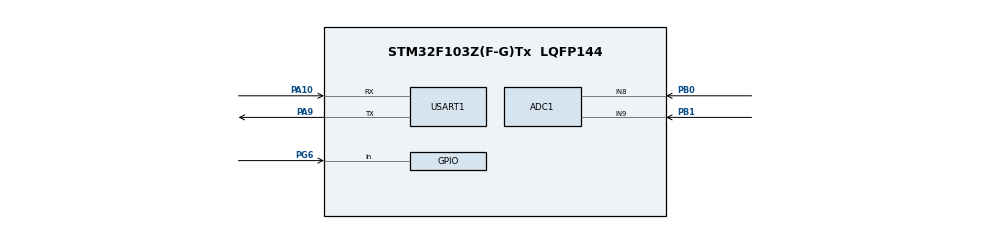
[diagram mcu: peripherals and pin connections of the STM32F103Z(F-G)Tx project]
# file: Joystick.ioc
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ADC1.Channel-2\#ChannelRegularConversion=ADC_CHANNEL_8
ADC1.Channel-3\#ChannelRegularConversion=ADC_CHANNEL_9
ADC1.DiscontinuousConvMode=ENABLE
ADC1.EnableRegularConversion=ENABLE
ADC1.NbrOfConversion=2
ADC1.NbrOfConversionFlag=1
ADC1.NbrOfDiscConversion=1
ADC1.Rank-2\#ChannelRegularConversion=1
ADC1.Rank-3\#ChannelRegularConversion=2
ADC1.SamplingTime-2\#ChannelRegularConversion=ADC_SAMPLETIME_1CYCLE_5
ADC1.SamplingTime-3\#ChannelRegularConversion=ADC_SAMPLETIME_1CYCLE_5
ADC1.master=1
Mcu.Family=STM32F1
Mcu.Name=STM32F103Z(F-G)Tx
Mcu.Package=LQFP144
NVIC.PriorityGroup=NVIC_PRIORITYGROUP_4
PA10.Mode=Asynchronous
PA10.Signal=USART1_RX
PA13.Mode=Serial_Wire
PA13.Signal=SYS_JTMS-SWDIO
PA14.Mode=Serial_Wire
PA14.Signal=SYS_JTCK-SWCLK
PA9.Mode=Asynchronous
PA9.Signal=USART1_TX
PB0.Signal=ADCx_IN8
PB1.Signal=ADCx_IN9
PG6.Signal=GPIO_Input
ProjectManager.HeapSize=0x200
ProjectManager.StackSize=0x400
ProjectManager.TargetToolchain=MDK-ARM V5.27
RCC.APB1Freq_Value=8000000
RCC.APB2Freq_Value=8000000
SH.ADCx_IN8.0=ADC1_IN8,IN8
SH.ADCx_IN9.0=ADC1_IN9,IN9
USART1.VirtualMode=VM_ASYNC
board=custom

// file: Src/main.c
/* USER CODE BEGIN Header */
/**
  ******************************************************************************
  * @file           : main.c
  * @brief          : Main program body
  ******************************************************************************
  * @attention
  *
  * <h2><center>&copy; Copyright (c) 2019 STMicroelectronics.
  * All rights reserved.</center></h2>
  *
  * This software component is licensed by ST under BSD 3-Clause license,
  * the "License"; You may not use this file except in compliance with the
  * License. You may obtain a copy of the License at:
  *                        opensource.org/licenses/BSD-3-Clause
  *
  ******************************************************************************
  */
/* USER CODE END Header */

#include "main.h"

ADC_HandleTypeDef hadc1;

UART_HandleTypeDef huart1;

void SystemClock_Config(void);
static void MX_GPIO_Init(void);
static void MX_ADC1_Init(void);
static void MX_USART1_UART_Init(void);

int main(void)
{

  /* MCU Configuration--------------------------------------------------------*/

  /* Reset of all peripherals, Initializes the Flash interface and the Systick. */
  HAL_Init();

  /* Configure the system clock */
  SystemClock_Config();

  /* Initialize all configured peripherals */
  MX_GPIO_Init();
  MX_ADC1_Init();
  MX_USART1_UART_Init();
  /* USER CODE BEGIN 2 */
  uint32_t x, y;
  /* USER CODE END 2 */

  /* Infinite loop */
  /* USER CODE BEGIN WHILE */
  while (1)
  {
    // Get x position from joystick
  	HAL_ADC_Start(&hadc1);
  	HAL_ADC_PollForConversion(&hadc1, 10);
  	x = HAL_ADC_GetValue(&hadc1);

    // Get y position from joystick
  	HAL_ADC_Start(&hadc1);
  	HAL_ADC_PollForConversion(&hadc1, 10);
  	y = HAL_ADC_GetValue(&hadc1);

    // Print x, y position
  	printf("%d,%d\r\n", x, y);

  	HAL_Delay(10);

    /* USER CODE END WHILE */

  }
}

void SystemClock_Config(void)
{
  RCC_OscInitTypeDef RCC_OscInitStruct = {0};
  RCC_ClkInitTypeDef RCC_ClkInitStruct = {0};
  RCC_PeriphCLKInitTypeDef PeriphClkInit = {0};

  /** Initializes the CPU, AHB and APB busses clocks
  */
  RCC_OscInitStruct.OscillatorType = RCC_OSCILLATORTYPE_HSI;
  RCC_OscInitStruct.HSIState = RCC_HSI_ON;
  RCC_OscInitStruct.HSICalibrationValue = RCC_HSICALIBRATION_DEFAULT;
  RCC_OscInitStruct.PLL.PLLState = RCC_PLL_NONE;
  if (HAL_RCC_OscConfig(&RCC_OscInitStruct) != HAL_OK)
  {
    Error_Handler();
  }
  /** Initializes the CPU, AHB and APB busses clocks
  */
  RCC_ClkInitStruct.ClockType = RCC_CLOCKTYPE_HCLK|RCC_CLOCKTYPE_SYSCLK
                              |RCC_CLOCKTYPE_PCLK1|RCC_CLOCKTYPE_PCLK2;
  RCC_ClkInitStruct.SYSCLKSource = RCC_SYSCLKSOURCE_HSI;
  RCC_ClkInitStruct.AHBCLKDivider = RCC_SYSCLK_DIV1;
  RCC_ClkInitStruct.APB1CLKDivider = RCC_HCLK_DIV1;
  RCC_ClkInitStruct.APB2CLKDivider = RCC_HCLK_DIV1;

  if (HAL_RCC_ClockConfig(&RCC_ClkInitStruct, FLASH_LATENCY_0) != HAL_OK)
  {
    Error_Handler();
  }
  PeriphClkInit.PeriphClockSelection = RCC_PERIPHCLK_ADC;
  PeriphClkInit.AdcClockSelection = RCC_ADCPCLK2_DIV2;
  if (HAL_RCCEx_PeriphCLKConfig(&PeriphClkInit) != HAL_OK)
  {
    Error_Handler();
  }
}

static void MX_ADC1_Init(void)
{

  ADC_ChannelConfTypeDef sConfig = {0};

  /** Common config
  */
  hadc1.Instance = ADC1;
  hadc1.Init.ScanConvMode = ADC_SCAN_ENABLE;
  hadc1.Init.ContinuousConvMode = DISABLE;
  hadc1.Init.DiscontinuousConvMode = ENABLE;
  hadc1.Init.NbrOfDiscConversion = 1;
  hadc1.Init.ExternalTrigConv = ADC_SOFTWARE_START;
  hadc1.Init.DataAlign = ADC_DATAALIGN_RIGHT;
  hadc1.Init.NbrOfConversion = 2;
  if (HAL_ADC_Init(&hadc1) != HAL_OK)
  {
    Error_Handler();
  }
  /** Configure Regular Channel
  */
  sConfig.Channel = ADC_CHANNEL_8;
  sConfig.Rank = ADC_REGULAR_RANK_1;
  sConfig.SamplingTime = ADC_SAMPLETIME_1CYCLE_5;
  if (HAL_ADC_ConfigChannel(&hadc1, &sConfig) != HAL_OK)
  {
    Error_Handler();
  }
  /** Configure Regular Channel
  */
  sConfig.Channel = ADC_CHANNEL_9;
  sConfig.Rank = ADC_REGULAR_RANK_2;
  if (HAL_ADC_ConfigChannel(&hadc1, &sConfig) != HAL_OK)
  {
    Error_Handler();
  }

}

static void MX_USART1_UART_Init(void)
{

  huart1.Instance = USART1;
  huart1.Init.BaudRate = 115200;
  huart1.Init.WordLength = UART_WORDLENGTH_8B;
  huart1.Init.StopBits = UART_STOPBITS_1;
  huart1.Init.Parity = UART_PARITY_NONE;
  huart1.Init.Mode = UART_MODE_TX_RX;
  huart1.Init.HwFlowCtl = UART_HWCONTROL_NONE;
  huart1.Init.OverSampling = UART_OVERSAMPLING_16;
  if (HAL_UART_Init(&huart1) != HAL_OK)
  {
    Error_Handler();
  }

}

static void MX_GPIO_Init(void)
{
  GPIO_InitTypeDef GPIO_InitStruct = {0};

  /* GPIO Ports Clock Enable */
  __HAL_RCC_GPIOB_CLK_ENABLE();
  __HAL_RCC_GPIOG_CLK_ENABLE();
  __HAL_RCC_GPIOA_CLK_ENABLE();

  /*Configure GPIO pin : PG6 */
  GPIO_InitStruct.Pin = GPIO_PIN_6;
  GPIO_InitStruct.Mode = GPIO_MODE_INPUT;
  GPIO_InitStruct.Pull = GPIO_NOPULL;
  HAL_GPIO_Init(GPIOG, &GPIO_InitStruct);

}

void Error_Handler(void)
{
}

/************************ (C) COPYRIGHT STMicroelectronics *****END OF FILE****/
